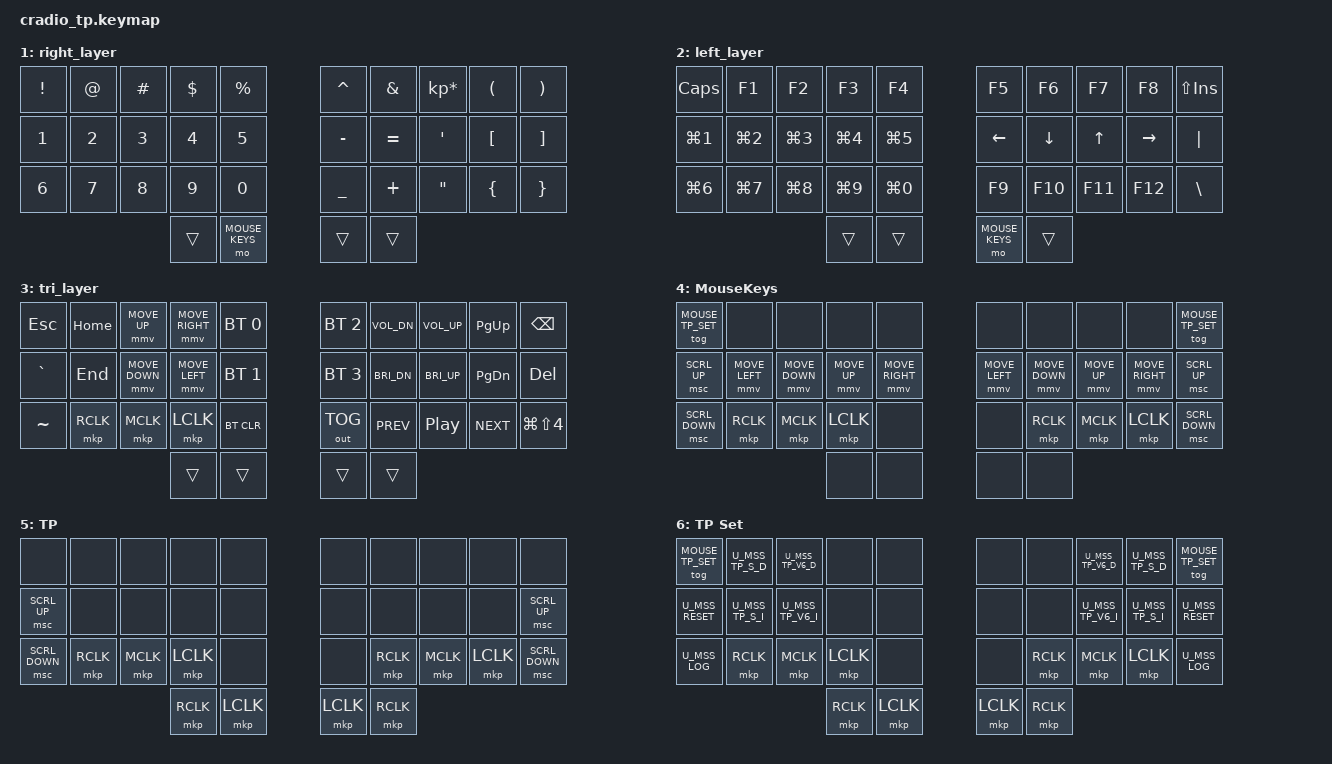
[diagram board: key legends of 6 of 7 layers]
// Copyright (c) 2022 The ZMK Contributors
// SPDX-License-Identifier: MIT

#include <behaviors.dtsi>
#include <dt-bindings/zmk/keys.h>
#include <dt-bindings/zmk/bt.h>
#include <dt-bindings/zmk/outputs.h>

#define MOUSE_KEYS 4
#define MOUSE_TP 5
#define MOUSE_TP_SET 6
#define HAS_MOUSE_KEYS
#define HAS_MOUSE_TP

#ifdef HAS_MOUSE_KEYS
  #include <dt-bindings/zmk/mouse.h>
  #include <behaviors/mouse_keys.dtsi>
#endif  // HAS_MOUSE_KEYS

#ifdef HAS_MOUSE_TP
  // We store the trackpoint settings in a separate file
  // to make organization a little easier.
  #include "include/mouse_tp.dtsi"
#endif  // HAS_MOUSE_TP



// Adjust layer keys based on enabled features.
//
// This prevents build errors when we build the firmware
// without the mouse keys PR or the TP module.
#ifdef HAS_MOUSE_KEYS
  #define U_THUMB_INNER &mo MOUSE_KEYS
#else
  #define U_THUMB_INNER &none
#endif  // HAS_MOUSE_KEYS

#ifdef HAS_MOUSE_TP
  #define U_TOG_TP_SET &tog MOUSE_TP_SET
#else
  #define U_TOG_TP_SET &none
#endif  // HAS_MOUSE_TP

// Home row mods macro
#define HRML(k1,k2,k3,k4) &ht LCTRL k1  &ht LALT k2  &ht LSHFT k3  &ht LGUI k4
#define HRMR(k1,k2,k3,k4) &ht RGUI k1  &ht LSHFT k2  &ht RALT k3  &ht RCTRL k4

/ {
	behaviors {
		ht: hold_tap {
			label = "hold_tap";
			compatible = "zmk,behavior-hold-tap";
			#binding-cells = <2>;
			flavor = "tap-preferred";
			tapping-term-ms = <220>;
			quick-tap-ms = <120>;
			require-prior-idle-ms = <100>;
			//global-quick-tap;
			bindings = <&kp>, <&kp>;
			//quick-tap-ms = <0>;
		};
    };

    conditional_layers {
        compatible = "zmk,conditional-layers";
        tri_layer {
            if-layers = <1 2>;
            then-layer = <3>;
        };
    };

    keymap {
        compatible = "zmk,keymap";
        default_layer {
            bindings = <
        //╭──────────┬──────────┬──────────┬──────────┬──────────╮   ╭──────────┬──────────┬──────────┬──────────┬──────────╮
        //│  Q       │  W       │  E       │  R       │  T       │   │  Y       │  U       │  I       │  O       │  P       │
            &kp Q      &kp W      &kp E      &kp R      &kp T          &kp Y      &kp U      &kp I      &kp O      &kp P
        //├──────────┼──────────┼──────────┼──────────┼──────────┤   ├──────────┼──────────┼──────────┼──────────┼──────────┤
        //│  A       │  S       │  D       │  F       │  G       │   │  H       │  J       │  K       │  L       │ ' "      │
            HRML(A,        S,         D,         F)     &kp G          &kp H      HRMR(J,        K,         L,        SEMI)
        //├──────────┼──────────┼──────────┼──────────┼──────────┤   ├──────────┼──────────┼──────────┼──────────┼──────────┤
        //│  Z       │  X       │  C       │  V       │  B       │   │  N       │  M       │ , <      │ . >      │ / ?      │
            &kp Z      &kp X      &kp C      &kp V      &kp B          &kp N      &kp M      &kp COMMA  &kp DOT    &kp FSLH
        //╰──────────┴──────────┴──────────┼──────────┼──────────┤   ├──────────┼──────────┼──────────┴──────────┴──────────╯
                                            &lt 2 TAB   &ht LGUI SPACE     &kp ENTER  &lt 1 BSPC
        //                                 ╰──────────┴──────────╯   ╰──────────┴──────────╯
            >;
        };

        right_layer {
            bindings = <
        //╭──────────┬──────────┬──────────┬──────────┬──────────╮   ╭──────────┬──────────┬──────────┬──────────┬──────────╮
        //│ INSERT   │  1       │  2       │  3       │          │   │ HOME     │ PAGE DN  │ PAGE UP  │ END      │  :       │
        //  &kp INS    &kp N1     &kp N2     &kp N3     &trans         &kp HOME   &kp PG_DN  &kp PG_UP  &kp END    &kp COLON
        //├──────────┼──────────┼──────────┼──────────┼──────────┤   ├──────────┼──────────┼──────────┼──────────┼──────────┤
        //│ DELETE   │  4       │  5       │  6       │          │   │ LEFT     │ DOWN     │ UP       │ RIGHT    │  ;       │
        //  &kp DEL    &kp N4     &kp N5     &kp N6     &trans         &kp LARW   &kp DARW   &kp UARW   &kp RARW   &kp SEMI
        //├──────────┼──────────┼──────────┼──────────┼──────────┤   ├──────────┼──────────┼──────────┼──────────┼──────────┤
        //│ CAPS     │  7       │  8       │  9       │  0       │   │          │          │          │          │          │
        // &caps_word  &kp N7     &kp N8     &kp N9     &kp N0         &trans     &trans     &trans     &trans     &trans
        //╰──────────┴──────────┴──────────┼──────────┼──────────┤   ├──────────┼──────────┼──────────┴──────────┴──────────╯
        //                                   &trans     &kp ESC        &trans     &trans
        //                                 ╰──────────┴──────────╯   ╰──────────┴──────────╯
            &kp EXCL &kp AT &kp HASH &kp DLLR &kp PRCNT                &kp CARET &kp AMPS  &kp KP_MULTIPLY &kp LPAR &kp RPAR 
            &kp N1 &kp N2 &kp N3 &kp N4 &kp N5						             &kp MINUS &kp EQUAL &kp SQT &kp LBKT &kp RBKT 
            &kp N6 &kp N7 &kp N8 &kp N9 &kp N0						             &kp UNDER &kp PLUS  &kp DQT &kp LBRC &kp RBRC
                                 &trans     U_THUMB_INNER 				&trans     &trans
            >;
        };

        left_layer {
            bindings = <
        //╭──────────┬──────────┬──────────┬──────────┬──────────╮   ╭──────────┬──────────┬──────────┬──────────┬──────────╮
        //│          │  [       │  {       │  }       │          │   │  ^       │  (       │  )       │  ]       │  ~       │
        //  &trans     &kp LBKT   &kp LBRC   &kp RBRC   &trans         &kp CARET  &kp LPAR   &kp RPAR   &kp RBKT   &kp TILDE
        //├──────────┼──────────┼──────────┼──────────┼──────────┤   ├──────────┼──────────┼──────────┼──────────┼──────────┤
        //│  !       │  @       │  #       │  $       │  %       │   │  *       │  -       │  =       │  \       │  `       │
        //  &kp EXCL   &kp AT     &kp HASH   &kp DLLR   &kp PRCNT      &kp ASTRK  &kp MINUS  &kp EQUAL  &kp BSLH   &kp GRAVE
        //├──────────┼──────────┼──────────┼──────────┼──────────┤   ├──────────┼──────────┼──────────┼──────────┼──────────┤
        //│          │          │          │          │          │   │  &       │  _       │  +       │  │       │          │
        //  &trans     &trans     &trans     &trans     &trans         &kp AMPS   &kp UNDER  &kp PLUS   &kp PIPE   &trans
        //╰──────────┴──────────┴──────────┼──────────┼──────────┤   ├──────────┼──────────┼──────────┴──────────┴──────────╯
        //                                   &trans     &trans         &trans     &trans
        //                                 ╰──────────┴──────────╯   ╰──────────┴──────────╯
            &kp CAPS &kp F1 &kp F2 &kp F3 &kp F4                        &kp F5 &kp F6 &kp F7 &kp F8  &kp LS(INS) 
            &kp LG(N1) &kp LG(N2) &kp LG(N3) &kp LG(N4) &kp LG(N5)      &kp LEFT &kp DOWN &kp UP &kp RIGHT &kp PIPE 
            &kp LG(N6) &kp LG(N7) &kp LG(N8) &kp LG(N9) &kp LG(N0)      &kp F9 &kp F10 &kp F11 &kp F12 &kp BSLH 
                                                 &trans     &trans      U_THUMB_INNER 		&trans
            >;
        };

        tri_layer {
            bindings = <
        //╭──────────┬──────────┬──────────┬──────────┬──────────╮   ╭──────────┬──────────┬──────────┬──────────┬──────────╮
        //│ RESET    │          │          │          │PROFILE 0 │   │PROFILE 2 │VOL DN    │VOL UP    │ PG UP    │   BSPC   │
           &kp ESC &kp HOME &mmv MOVE_UP &mmv MOVE_RIGHT &bt BT_SEL 0   &bt BT_SEL 2 &kp C_VOL_DN &kp C_VOL_UP &kp PG_UP &kp BSPC
        //├──────────┼──────────┼──────────┼──────────┼──────────┤   ├──────────┼──────────┼──────────┼──────────┼──────────┤
        //│BOOTLOADER│          │          │          │PROFILE 1 │   │ PROFILE 3│DEC BRIGHT│INC BRIGHT│ PG DN    │   DEL    │
           &kp GRAVE  &kp END &mmv MOVE_DOWN &mmv MOVE_LEFT &bt BT_SEL 1   &bt BT_SEL 3 &kp C_BRI_DN &kp C_BRI_UP &kp PG_DN &kp DEL
        //├──────────┼──────────┼──────────┼──────────┼──────────┤   ├──────────┼──────────┼──────────┼──────────┼──────────┤
        //│          │          │          │          │CLEAR BT  │   |SWITCH_OUT│ PREVSONG │PAUSEMUSIC│ NEXTSONG │          │
           &kp TILDE  &mkp RCLK  &mkp MCLK  &mkp LCLK  &bt BT_CLR     &out OUT_TOG &kp C_PREV &kp C_PP &kp C_NEXT &kp LG(LS(N4))
        //╰──────────┴──────────┴──────────┼──────────┼──────────┤   ├──────────┼──────────┼──────────┴──────────┴──────────╯
                                           &trans     &trans         &trans     &trans
        //                                 ╰──────────┴──────────╯   ╰──────────┴──────────╯
            >;
        };

#ifdef HAS_MOUSE_KEYS

    MouseKeys_layer {
      display-name = "MouseKeys";
      bindings = <
// ╭------------┬------------┬------------┬------------┬------------┬------------╮    ╭------------┬------------┬------------┬------------┬------------┬------------╮
     U_TOG_TP_SET    &none    &none &none   &none		    				           &none    &none  &none    &none   U_TOG_TP_SET    
// ├------------┼------------┼------------┼------------┼------------┼------------┤    ├------------┼------------┼------------┼------------┼------------┼------------┤
     &msc SCRL_UP &mmv MOVE_LEFT &mmv MOVE_DOWN &mmv MOVE_UP &mmv MOVE_RIGHT           &mmv MOVE_LEFT &mmv MOVE_DOWN &mmv MOVE_UP &mmv MOVE_RIGHT &msc SCRL_UP 
// ├------------┼------------┼------------┼------------┼------------┼------------┤    ├------------┼------------┼------------┼------------┼------------┼------------┤
     &msc SCRL_DOWN &mkp RCLK &mkp MCLK &mkp LCLK &none                                &none &mkp RCLK &mkp MCLK &mkp LCLK &msc SCRL_DOWN
// ╰------------┴------------┴------------┴------------┼------------┼------------┤    ├------------┼------------┼------------┼------------┴------------┼------------╯
    													&none   &none                  &none   &none   
// 										╰------------┴------------┴------------╯    	╰------------┴------------┴------------╯
      >;
    };

#endif

#ifdef HAS_MOUSE_TP

    // Automatically activated when the mouse or trackpoint moves.
    // Configured in `include/mouse_tp.dtsi`.
    MouseTP_layer {
      display-name = "TP";
      bindings = <
// ╭------------┬------------┬------------┬------------┬------------┬------------╮    ╭------------┬------------┬------------┬------------┬------------┬------------╮
     &none   &none    &none &none   &none		    				                   &none    &none  &none    &none   &none  
// ├------------┼------------┼------------┼------------┼------------┼------------┤    ├------------┼------------┼------------┼------------┼------------┼------------┤
     &msc SCRL_UP &none    &none  &none    &none                                       &none    &none  &none    &none  &msc SCRL_UP 
// ├------------┼------------┼------------┼------------┼------------┼------------┤    ├------------┼------------┼------------┼------------┼------------┼------------┤
     &msc SCRL_DOWN &mkp RCLK &mkp MCLK &mkp LCLK &none                                &none &mkp RCLK &mkp MCLK &mkp LCLK &msc SCRL_DOWN
// ╰------------┴------------┴------------┴------------┼------------┼------------┤    ├------------┼------------┼------------┼------------┴------------┼------------╯
    													      &mkp RCLK &mkp LCLK      &mkp LCLK &mkp RCLK
// 										╰------------┴------------┴------------╯    	╰------------┴------------┴------------╯
      >;
    };

    // You can find the defines for the actual key press behaviors in `include/mouse_tp.dtsi`.
    MouseSettings_layer {
      display-name = "TP Set";
      bindings = <
// ╭------------┬------------┬------------┬------------┬------------┬------------╮    ╭------------┬------------┬------------┬------------┬------------┬------------╮
     U_TOG_TP_SET U_MSS_TP_S_D  U_MSS_TP_V6_D &none &none                              &none &none U_MSS_TP_V6_D U_MSS_TP_S_D U_TOG_TP_SET    
// ├------------┼------------┼------------┼------------┼------------┼------------┤    ├------------┼------------┼------------┼------------┼------------┼------------┤
     U_MSS_RESET  U_MSS_TP_S_I  U_MSS_TP_V6_I &none &none                              &none &none U_MSS_TP_V6_I U_MSS_TP_S_I U_MSS_RESET    
// ├------------┼------------┼------------┼------------┼------------┼------------┤    ├------------┼------------┼------------┼------------┼------------┼------------┤
     U_MSS_LOG    &mkp RCLK &mkp MCLK &mkp LCLK &none                                  &none &mkp RCLK &mkp MCLK &mkp LCLK U_MSS_LOG    
// ╰------------┴------------┴------------┴------------┼------------┼------------┤    ├------------┼------------┼------------┼------------┴------------┼------------╯
    													      &mkp RCLK &mkp LCLK      &mkp LCLK &mkp RCLK
// 										╰------------┴------------┴------------╯    	╰------------┴------------┴------------╯
      >;
    };

#endif
    };
};
